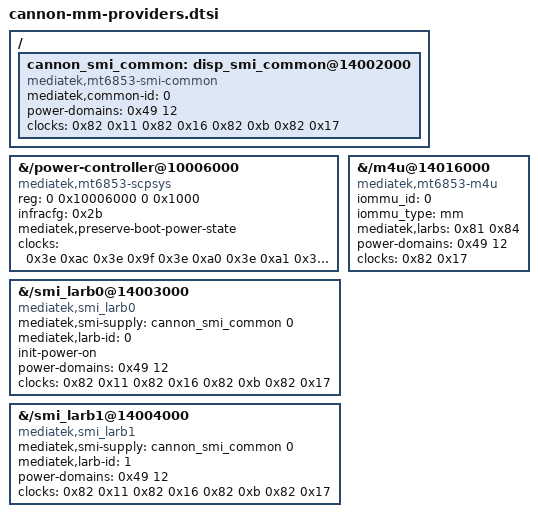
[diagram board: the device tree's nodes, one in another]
// SPDX-License-Identifier: (GPL-2.0 OR MIT)
// MT6853 provider bindings from the 6.12 mt6853.dtsi.
// Clock selectors use cannon's preserved 4.14 DT ID namespace.
// SCPSYS adoption, SMI runtime PM and IOMMU mappings verified on test55.

&{/power-controller@10006000} {
 compatible = "mediatek,mt6853-scpsys", "syscon";
 reg = <0 0x10006000 0 0x1000>;
 /delete-property/ #clock-cells;
 #power-domain-cells = <1>;
 infracfg = <0x2b>;
 mediatek,preserve-boot-power-state;
 clocks = <0x3e 0xac 0x3e 0x9f 0x3e 0xa0 0x3e 0xa1 0x3e 0xce 0x3e 0xcd 0x3e 0x9e 0x3e 0x9d 0x3e 0xb8 0x3e 0xcb 0x3e 0xa3 0x9a 0x0 0x9a 0x3 0x9b 0x0 0x9b 0x1 0x9b 0x5 0x8a 0x0 0x8a 0x1 0x8a 0x2 0x8a 0x7 0x87 0x1 0x87 0x0 0x9d 0x1 0x86 0x6 0x82 0xb 0x82 0x11 0x82 0x16 0x82 0x17 0x2b 0x37 0x2b 0x2e 0x7c 0x0 0x7c 0x1 0x7c 0xe 0x7c 0xf 0x88 0x0 0x89 0x0>;
 clock-names = "mfg", "isp", "isp2", "ipe",
				"vdec", "venc", "mdp", "disp",
				"audio", "adsp", "cam", "isp-0",
				"isp-1", "isp2-0", "isp2-1", "isp2-2",
				"ipe-0", "ipe-1", "ipe-2", "ipe-3",
				"vdec-0", "vdec-1", "venc-0", "disp-0",
				"disp-1", "disp-2", "disp-3", "disp-4",
				"audio-0", "audio-1", "cam-0", "cam-1",
				"cam-2", "cam-3", "cam_rawa-0", "cam_rawb-0";
};

&{/disp_smi_common@14002000} {
 compatible = "mediatek,mt6853-smi-common", "syscon", "mediatek,smi-common";
 mediatek,common-id = <0>;
 power-domains = <0x49 12>;
 clocks = <0x82 0x11 0x82 0x16 0x82 0xb 0x82 0x17>;
 clock-names = "apb", "smi", "gals0", "gals1";
};

&{/smi_larb0@14003000} {
 compatible = "mediatek,smi_larb0", "mediatek,mt6853-smi-larb", "mediatek,smi-larb";
 mediatek,smi-supply = <&cannon_smi_common 0>;
 mediatek,larb-id = <0>;
 init-power-on;
 power-domains = <0x49 12>;
 clocks = <0x82 0x11 0x82 0x16 0x82 0xb 0x82 0x17>;
 clock-names = "apb", "smi", "gals0", "gals1";
};

&{/smi_larb1@14004000} {
 compatible = "mediatek,smi_larb1", "mediatek,mt6853-smi-larb", "mediatek,smi-larb";
 mediatek,smi-supply = <&cannon_smi_common 0>;
 mediatek,larb-id = <1>;
 power-domains = <0x49 12>;
 clocks = <0x82 0x11 0x82 0x16 0x82 0xb 0x82 0x17>;
 clock-names = "apb", "smi", "gals0", "gals1";
};

&{/m4u@14016000} {
 compatible = "mediatek,mt6853-m4u";
 iommu_id = <0>;
 iommu_type = "mm";
 mediatek,larbs = <0x81 0x84>;
 power-domains = <0x49 12>;
 clocks = <0x82 0x17>;
 clock-names = "bclk";
};

// Preserve all existing numeric phandles, adding a local label only.
/ { cannon_smi_common: disp_smi_common@14002000 {}; };
